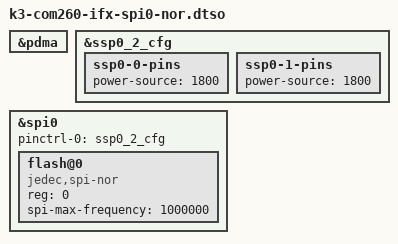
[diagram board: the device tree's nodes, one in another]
// SPDX-License-Identifier: (GPL-2.0 OR MIT)

/dts-v1/;
/plugin/;

&pdma {
	status = "okay";
};

&ssp0_2_cfg {
	ssp0-0-pins {
		power-source = <1800>;
	};

	ssp0-1-pins {
		power-source = <1800>;
	};
};

&spi0 {
	#address-cells = <1>;
	#size-cells = <0>;

	pinctrl-names = "default";
	pinctrl-0 = <&ssp0_2_cfg>;
	status = "okay";

	flash@0 {
		compatible = "jedec,spi-nor";
		reg = <0>;
		spi-max-frequency = <1000000>;
	};
};
